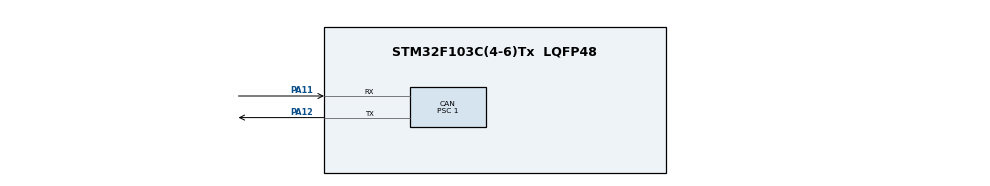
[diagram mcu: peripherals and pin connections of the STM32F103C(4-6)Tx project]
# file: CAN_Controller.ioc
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CAN.BS1=CAN_BS1_6TQ
CAN.CalculateTimeBit=1000
CAN.CalculateTimeQuantum=125.0
CAN.Mode=CAN_MODE_LOOPBACK
CAN.NART=ENABLE
CAN.Prescaler=1
Mcu.Family=STM32F1
Mcu.Name=STM32F103C(4-6)Tx
Mcu.Package=LQFP48
NVIC.PriorityGroup=NVIC_PRIORITYGROUP_4
PA11.Mode=Master
PA11.Signal=CAN_RX
PA12.Mode=Master
PA12.Signal=CAN_TX
PA13.Mode=Serial_Wire
PA13.Signal=SYS_JTMS-SWDIO
PA14.Mode=Serial_Wire
PA14.Signal=SYS_JTCK-SWCLK
ProjectManager.HeapSize=0x200
ProjectManager.StackSize=0x400
ProjectManager.TargetToolchain=STM32CubeIDE
RCC.APB1Freq_Value=8000000
RCC.APB2Freq_Value=8000000
board=custom

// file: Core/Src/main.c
/* USER CODE BEGIN Header */
/**
  ******************************************************************************
  * @file           : main.c
  * @brief          : Main program body
  ******************************************************************************
  * @attention
  *
  * <h2><center>&copy; Copyright (c) 2023 STMicroelectronics.
  * All rights reserved.</center></h2>
  *
  * This software component is licensed by ST under BSD 3-Clause license,
  * the "License"; You may not use this file except in compliance with the
  * License. You may obtain a copy of the License at:
  *                        opensource.org/licenses/BSD-3-Clause
  *
  ******************************************************************************
  */
/* USER CODE END Header */
#include "main.h"
#include "../stm32f1xx_hal_can.h"

CAN_HandleTypeDef hcan;

void SystemClock_Config(void);
static void MX_GPIO_Init(void);
static void MX_CAN_Init(void);

/* USER CODE BEGIN 0 */

void CAN_voidSendPacket(uint32_t ID , uint8_t DLC, uint8_t *p_Data)
{
	uint8_t pTxMailbox ;
	HAL_StatusTypeDef HAL_Status ;
	CAN_TxHeaderTypeDef pHeader ;
	// TX Header
	pHeader.DLC = DLC ;
	pHeader.IDE = DISABLE ;
	pHeader.RTR = CAN_RTR_DATA ;
	pHeader.StdId = ID ;
	pTxMailbox = (uint8_t)HAL_CAN_GetTxMailboxesFreeLevel(&hcan);
	if(pTxMailbox > 0)
	{
		// Exist Free Mail-Box
		HAL_Status = HAL_CAN_AddTxMessage(&hcan, &pHeader,p_Data,(uint32_t*)&pTxMailbox);
		if (HAL_Status != HAL_OK)
		{
			Error_Handler();
		}

		// Poling On Data
		while ( HAL_CAN_IsTxMessagePending (&hcan, (uint32_t)pTxMailbox) ) ;
	}

}

void   CAN_voidID_Filter(uint16_t ID , uint16_t mask , uint8_t filterBankNum)
{
	// 9-bit id and mask
	ID = ID &(0b111111111000) ;
	mask = mask &(0b111111111000) ;

	CAN_FilterTypeDef sFilterConfig ;
	sFilterConfig.FilterActivation= CAN_FILTER_ENABLE;
	sFilterConfig.FilterBank= filterBankNum ;
	sFilterConfig.FilterFIFOAssignment = CAN_FILTER_FIFO0 ;
	sFilterConfig.FilterIdHigh = (ID << 5) ;
	sFilterConfig.FilterIdLow = 0x0000 ;
	sFilterConfig.FilterMaskIdHigh = (mask << 5) ;
	sFilterConfig.FilterMaskIdLow = 0x0000 ;
	sFilterConfig.FilterMode = CAN_FILTERMODE_IDMASK ;
	sFilterConfig.FilterScale= CAN_FILTERSCALE_32BIT ;
	HAL_CAN_ConfigFilter(&hcan, &sFilterConfig);
}

void CAN_voidReceivePacket(uint32_t *ID , uint8_t *DLC, uint8_t *p_Data)
{
	CAN_RxHeaderTypeDef pHeader ;
	// Wait Until RX Packet be more than 1
	while (HAL_CAN_GetRxFifoFillLevel(&hcan, CAN_FILTER_FIFO0) == 0) ;
	// Get Packet
	HAL_CAN_GetRxMessage(&hcan, CAN_FILTER_FIFO0, &pHeader, p_Data);
	*DLC = pHeader.DLC ;
	*ID = pHeader.StdId ;
}

#define BUFFER_SIZE	4
uint8_t payload[BUFFER_SIZE] = {'C','A','N',' '};
uint8_t frameCounter ;

uint32_t RXID; uint8_t RXBUFFER[8];
uint8_t RXDLC ;
// 9-bit ID 0b0011 1111 1xxx
#define WORKING_ID	0x3ff
#define RX_MASK	    0b111100000000

/* USER CODE END 0 */
int main(void)
{

  /* MCU Configuration--------------------------------------------------------*/

  /* Reset of all peripherals, Initializes the Flash interface and the Systick. */
  HAL_Init();

  /* Configure the system clock */
  SystemClock_Config();

  /* Initialize all configured peripherals */
  MX_GPIO_Init();
  MX_CAN_Init();
  /* USER CODE BEGIN 2 */
  // Filtration
  CAN_voidID_Filter(WORKING_ID , RX_MASK, 0);

  HAL_CAN_Start(&hcan); //start CAN

  /* USER CODE END 2 */

  /* Infinite loop */
  /* USER CODE BEGIN WHILE */
  while (1)
  {
	  payload[BUFFER_SIZE-1] = frameCounter++ ;
	  CAN_voidSendPacket(0x1FF,BUFFER_SIZE, payload) ;
	  CAN_voidReceivePacket(&RXID, &RXDLC, RXBUFFER);
    /* USER CODE END WHILE */

  }
}

void SystemClock_Config(void)
{
  RCC_OscInitTypeDef RCC_OscInitStruct = {0};
  RCC_ClkInitTypeDef RCC_ClkInitStruct = {0};

  /** Initializes the RCC Oscillators according to the specified parameters
  * in the RCC_OscInitTypeDef structure.
  */
  RCC_OscInitStruct.OscillatorType = RCC_OSCILLATORTYPE_HSI;
  RCC_OscInitStruct.HSIState = RCC_HSI_ON;
  RCC_OscInitStruct.HSICalibrationValue = RCC_HSICALIBRATION_DEFAULT;
  RCC_OscInitStruct.PLL.PLLState = RCC_PLL_NONE;
  if (HAL_RCC_OscConfig(&RCC_OscInitStruct) != HAL_OK)
  {
    Error_Handler();
  }
  /** Initializes the CPU, AHB and APB buses clocks
  */
  RCC_ClkInitStruct.ClockType = RCC_CLOCKTYPE_HCLK|RCC_CLOCKTYPE_SYSCLK
                              |RCC_CLOCKTYPE_PCLK1|RCC_CLOCKTYPE_PCLK2;
  RCC_ClkInitStruct.SYSCLKSource = RCC_SYSCLKSOURCE_HSI;
  RCC_ClkInitStruct.AHBCLKDivider = RCC_SYSCLK_DIV1;
  RCC_ClkInitStruct.APB1CLKDivider = RCC_HCLK_DIV1;
  RCC_ClkInitStruct.APB2CLKDivider = RCC_HCLK_DIV1;

  if (HAL_RCC_ClockConfig(&RCC_ClkInitStruct, FLASH_LATENCY_0) != HAL_OK)
  {
    Error_Handler();
  }
}

static void MX_CAN_Init(void)
{

  hcan.Instance = CAN1;
  hcan.Init.Prescaler = 1;
  hcan.Init.Mode = CAN_MODE_LOOPBACK;
  hcan.Init.SyncJumpWidth = CAN_SJW_1TQ;
  hcan.Init.TimeSeg1 = CAN_BS1_6TQ;
  hcan.Init.TimeSeg2 = CAN_BS2_1TQ;
  hcan.Init.TimeTriggeredMode = DISABLE;
  hcan.Init.AutoBusOff = DISABLE;
  hcan.Init.AutoWakeUp = DISABLE;
  hcan.Init.AutoRetransmission = ENABLE;
  hcan.Init.ReceiveFifoLocked = DISABLE;
  hcan.Init.TransmitFifoPriority = DISABLE;
  if (HAL_CAN_Init(&hcan) != HAL_OK)
  {
    Error_Handler();
  }

}

static void MX_GPIO_Init(void)
{

  /* GPIO Ports Clock Enable */
  __HAL_RCC_GPIOA_CLK_ENABLE();

}

void Error_Handler(void)
{
}

/************************ (C) COPYRIGHT STMicroelectronics *****END OF FILE****/
